VERSION "HIPBNYYYYYYYYYYYYYYYYYYYYYYYYYYYYYYYYYYYYY/4/%%%/4/'%**4YYY///"

NS_ :

BS_:

BU_:

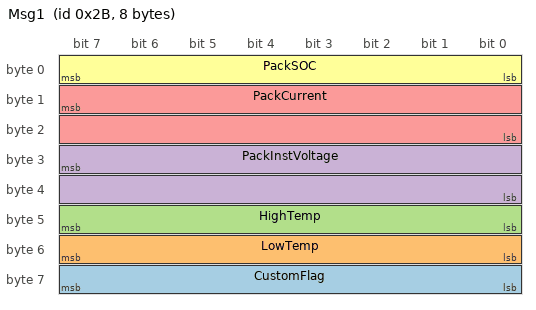
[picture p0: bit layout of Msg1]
BO_ 43 Msg1: 8 Vector__XXX
 SG_ CustomFlag : 63|8@0+ (1,0) [0|0] "" Vector__XXX
 SG_ LowTemp : 55|8@0+ (1,0) [0|0] "" Vector__XXX
 SG_ HighTemp : 47|8@0+ (1,0) [0|0] "" Vector__XXX
 SG_ PackInstVoltage : 31|16@0+ (0.1,0) [0|0] "" Vector__XXX
 SG_ PackCurrent : 15|16@0- (0.1,0) [0|0] "" Vector__XXX
 SG_ PackSOC : 7|8@0+ (1,0) [0|0] "" Vector__XXX

BO_ 44 Msg2: 2 Vector__XXX
 SG_ _12vSupply : 7|16@0+ (1,0) [0|0] "" Vector__XXX
